# MIMXRT1064 register map
Vendor: nxp.com; File version: 1.0
CPU: CM7 r0p1, little endian, MPU, FPU, VTOR, 4 interrupt priority bits
Registers are 32-bit, read-write, reset 0x0 unless marked. A register's access mark holds for its fields unless they carry their own. Offsets are from the block's base; [hi:lo] are bit positions; {n}, {i} and the like mark numbered series.

## GPT1 — GPT
Base 0x401EC000; register names take the prefix GPT1_
Same registers: GPT2 0x401F0000 (register names take the prefix GPT2_)
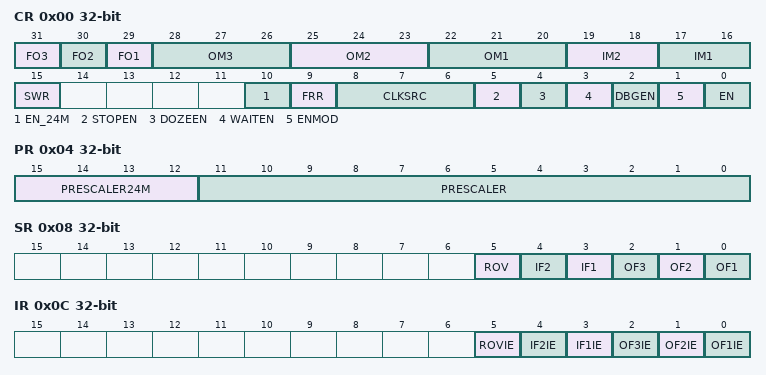
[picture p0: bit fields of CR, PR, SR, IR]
0x00 CR — GPT Control Register
  [31] FO3 — FO3 Force Output Compare Channel 3 FO2 Force Output Compare Channel 2 FO1 Force Output Compare Channel 1 The FOn bit causes the pin action programmed for the timer Output Compare n pin (according to the OMn bits in this register)
    0=Writing a 0 has no effect; 1=Causes the programmed pin action on the timer Output Compare n pin; the OFn flag is not set
  [30] FO2 — See F03
  [29] FO1 — See F03
  [28:26] OM3 — OM3 (bits 28-26) controls the Output Compare Channel 3 operating mode
    0=Output disconnected. No response on pin.; 1=Toggle output pin; 2=Clear output pin; 3=Set output pin; 0b1xx=Generate an active low pulse (that is one input clock wide) on the output pin
  [25:23] OM2 — See OM3
  [22:20] OM1 — See OM3
  [19:18] IM2 — IM2 (bits 19-18, Input Capture Channel 2 operating mode) IM1 (bits 17-16, Input Capture Channel 1 operating mode) The IMn bit field determines the transition on the input pin (for Input capture channel n), which will trigger a capture event
    0=capture disabled; 1=capture on rising edge only; 2=capture on falling edge only; 3=capture on both edges
  [17:16] IM1 — See IM2
  [15] SWR — Software reset
    0=GPT is not in reset state; 1=GPT is in reset state
  [10] EN_24M — Enable 24 MHz clock input from crystal
    0=24M clock disabled; 1=24M clock enabled
  [9] FRR — Free-Run or Restart mode
    0=Restart mode; 1=Free-Run mode
  [8:6] CLKSRC — Clock Source select
    0=No clock; 1=Peripheral Clock (ipg_clk); 2=High Frequency Reference Clock (ipg_clk_highfreq); 3=External Clock; 4=Low Frequency Reference Clock (ipg_clk_32k); 5=Crystal oscillator as Reference Clock (ipg_clk_24M)
  [5] STOPEN — GPT Stop Mode enable
    0=GPT is disabled in Stop mode; 1=GPT is enabled in Stop mode
  [4] DOZEEN — GPT Doze Mode Enable
    0=GPT is disabled in doze mode; 1=GPT is enabled in doze mode
  [3] WAITEN — GPT Wait Mode enable
    0=GPT is disabled in wait mode; 1=GPT is enabled in wait mode
  [2] DBGEN — GPT debug mode enable
    0=GPT is disabled in debug mode; 1=GPT is enabled in debug mode
  [1] ENMOD — GPT Enable mode
    0=GPT counter will retain its value when it is disabled; 1=GPT counter value is reset to 0 when it is disabled
  [0] EN — GPT Enable
    0=GPT is disabled; 1=GPT is enabled
0x04 PR — GPT Prescaler Register
  [15:12] PRESCALER24M — Prescaler bits
    0=Divide by 1; 1=Divide by 2; 15=Divide by 16
  [11:0] PRESCALER — Prescaler bits
    0=Divide by 1; 1=Divide by 2; 0xFFF=Divide by 4096
0x08 SR write-1-clears — GPT Status Register
  [5] ROV write-1-clears — Rollover Flag
    0=Rollover has not occurred; 1=Rollover has occurred
  [4] IF2 write-1-clears — IF2 Input capture 2 Flag IF1 Input capture 1 Flag The IFn bit indicates that a capture event has occurred on Input Capture channel n
    0=Capture event has not occurred; 1=Capture event has occurred
  [3] IF1 write-1-clears — See IF2
  [2] OF3 write-1-clears — OF3 Output Compare 3 Flag OF2 Output Compare 2 Flag OF1 Output Compare 1 Flag The OFn bit indicates that a compare event has occurred on Output Compare channel n
    0=Compare event has not occurred; 1=Compare event has occurred
  [1] OF2 write-1-clears — See OF3
  [0] OF1 write-1-clears — See OF3
0x0C IR — GPT Interrupt Register
  [5] ROVIE — Rollover Interrupt Enable. The ROVIE bit controls the Rollover interrupt.
    0=Rollover interrupt is disabled; 1=Rollover interrupt enabled
  [4] IF2IE — IF2IE Input capture 2 Interrupt Enable IF1IE Input capture 1 Interrupt Enable The IFnIE bit controls the IFnIE Input Capture n Interrupt Enable
    0=IF2IE Input Capture n Interrupt Enable is disabled; 1=IF2IE Input Capture n Interrupt Enable is enabled
  [3] IF1IE — See IF2IE
  [2] OF3IE — OF3IE Output Compare 3 Interrupt Enable OF2IE Output Compare 2 Interrupt Enable OF1IE Output Compare 1 Interrupt Enable The OFnIE bit controls the Output Compare Channel n interrupt
    0=Output Compare Channel n interrupt is disabled; 1=Output Compare Channel n interrupt is enabled
  [1] OF2IE — See OF3IE
  [0] OF1IE — See OF3IE
{0xC+4i} OCR{i} reset 0xFFFFFFFF (i=1..3) — GPT Output Compare Register {i}
  [31:0] COMP — Compare Value
0x1C ICR1 ro — GPT Input Capture Register 1
  [31:0] CAPT — Capture Value
0x20 ICR2 ro — GPT Input Capture Register 2
  [31:0] CAPT — Capture Value
0x24 CNT ro — GPT Counter Register
  [31:0] COUNT — Counter Value. The COUNT bits show the current count value of the GPT counter.
